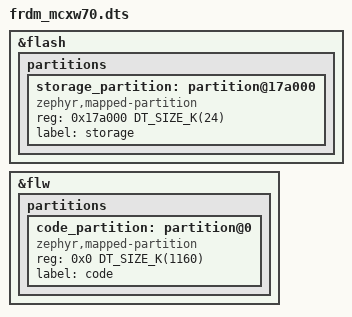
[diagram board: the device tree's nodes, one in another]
/*
 * Copyright 2026 NXP
 * SPDX-License-Identifier: Apache-2.0
 */

/dts-v1/;

#include <nxp/mcx/mcxw/nxp_mcxw70.dtsi>
#include "frdm_mcxw70_common.dtsi"

&flash {
	partitions {
		ranges;
		#address-cells = <1>;
		#size-cells = <1>;

		storage_partition: partition@17a000 {
			compatible = "zephyr,mapped-partition";
			reg = <0x17a000 DT_SIZE_K(24)>;
			label = "storage";
		};
	};
};

&flw {
	partitions {
		ranges;
		#address-cells = <1>;
		#size-cells = <1>;

		code_partition: partition@0 {
			compatible = "zephyr,mapped-partition";
			reg = <0x0 DT_SIZE_K(1160)>;
			label = "code";
		};
	};
};
